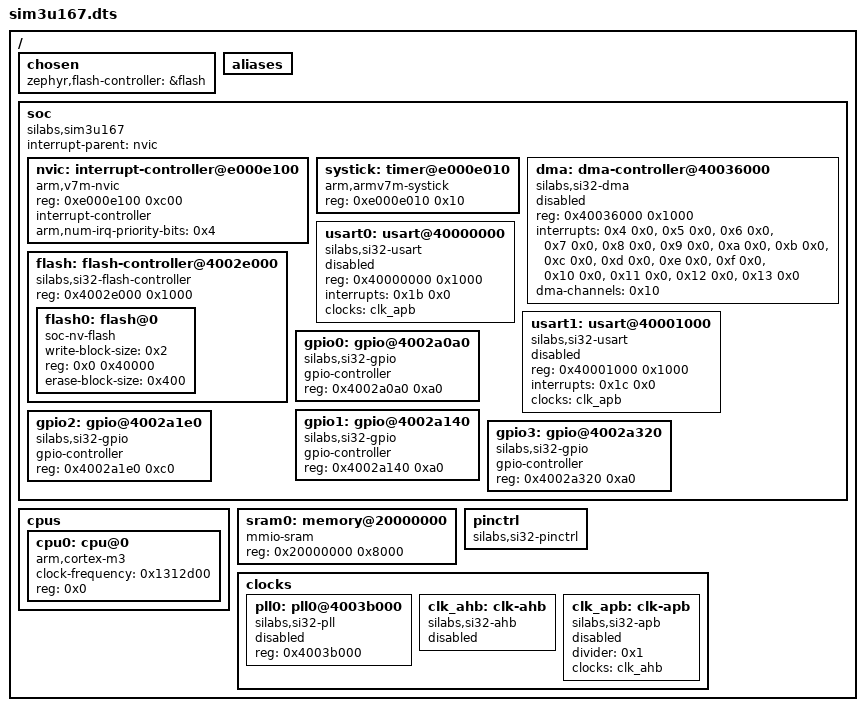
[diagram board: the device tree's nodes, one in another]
/dts-v1/;

/ {
	#address-cells = < 0x1 >;
	#size-cells = < 0x1 >;
	chosen {
		zephyr,flash-controller = &flash;
	};
	aliases {
	};
	soc {
		#address-cells = < 0x1 >;
		#size-cells = < 0x1 >;
		compatible = "silabs,sim3u167", "silabs,sim3u", "silabs,sim3", "simple-bus";
		interrupt-parent = < &nvic >;
		ranges;
		nvic: interrupt-controller@e000e100 {
			#address-cells = < 0x1 >;
			compatible = "arm,v7m-nvic";
			reg = < 0xe000e100 0xc00 >;
			interrupt-controller;
			#interrupt-cells = < 0x2 >;
			arm,num-irq-priority-bits = < 0x4 >;
			phandle = < 0x1 >;
		};
		systick: timer@e000e010 {
			compatible = "arm,armv7m-systick";
			reg = < 0xe000e010 0x10 >;
		};
		dma: dma-controller@40036000 {
			compatible = "silabs,si32-dma";
			reg = < 0x40036000 0x1000 >;
			interrupts = < 0x4 0x0 >, < 0x5 0x0 >, < 0x6 0x0 >, < 0x7 0x0 >, < 0x8 0x0 >, < 0x9 0x0 >, < 0xa 0x0 >, < 0xb 0x0 >, < 0xc 0x0 >, < 0xd 0x0 >, < 0xe 0x0 >, < 0xf 0x0 >, < 0x10 0x0 >, < 0x11 0x0 >, < 0x12 0x0 >, < 0x13 0x0 >;
			dma-channels = < 0x10 >;
			#dma-cells = < 0x3 >;
			status = "disabled";
		};
		flash: flash-controller@4002e000 {
			compatible = "silabs,si32-flash-controller";
			reg = < 0x4002e000 0x1000 >;
			#address-cells = < 0x1 >;
			#size-cells = < 0x1 >;
			flash0: flash@0 {
				compatible = "soc-nv-flash";
				write-block-size = < 0x2 >;
				reg = < 0x0 0x40000 >;
				erase-block-size = < 0x400 >;
			};
		};
		usart0: usart@40000000 {
			compatible = "silabs,si32-usart";
			reg = < 0x40000000 0x1000 >;
			interrupts = < 0x1b 0x0 >;
			clocks = < &clk_apb >;
			status = "disabled";
		};
		usart1: usart@40001000 {
			compatible = "silabs,si32-usart";
			reg = < 0x40001000 0x1000 >;
			interrupts = < 0x1c 0x0 >;
			clocks = < &clk_apb >;
			status = "disabled";
		};
		gpio0: gpio@4002a0a0 {
			compatible = "silabs,si32-gpio";
			gpio-controller;
			#gpio-cells = < 0x2 >;
			reg = < 0x4002a0a0 0xa0 >;
		};
		gpio1: gpio@4002a140 {
			compatible = "silabs,si32-gpio";
			gpio-controller;
			#gpio-cells = < 0x2 >;
			reg = < 0x4002a140 0xa0 >;
		};
		gpio2: gpio@4002a1e0 {
			compatible = "silabs,si32-gpio";
			gpio-controller;
			#gpio-cells = < 0x2 >;
			reg = < 0x4002a1e0 0xc0 >;
		};
		gpio3: gpio@4002a320 {
			compatible = "silabs,si32-gpio";
			gpio-controller;
			#gpio-cells = < 0x2 >;
			reg = < 0x4002a320 0xa0 >;
		};
	};
	cpus {
		#address-cells = < 0x1 >;
		#size-cells = < 0x0 >;
		cpu0: cpu@0 {
			compatible = "arm,cortex-m3";
			device_type = "cpu";
			clock-frequency = < 0x1312d00 >;
			reg = < 0x0 >;
		};
	};
	sram0: memory@20000000 {
		compatible = "mmio-sram";
		reg = < 0x20000000 0x8000 >;
	};
	pinctrl: pinctrl {
		compatible = "silabs,si32-pinctrl";
		status = "okay";
	};
	clocks {
		#address-cells = < 0x1 >;
		#size-cells = < 0x0 >;
		pll0: pll0@4003b000 {
			compatible = "silabs,si32-pll";
			#clock-cells = < 0x0 >;
			reg = < 0x4003b000 >;
			status = "disabled";
		};
		clk_ahb: clk-ahb {
			compatible = "silabs,si32-ahb";
			#clock-cells = < 0x0 >;
			status = "disabled";
			phandle = < 0x3 >;
		};
		clk_apb: clk-apb {
			compatible = "silabs,si32-apb";
			#clock-cells = < 0x0 >;
			divider = < 0x1 >;
			clocks = < &clk_ahb >;
			status = "disabled";
			phandle = < 0x2 >;
		};
	};
};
